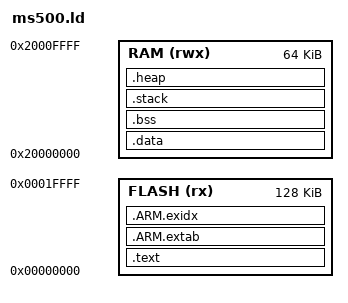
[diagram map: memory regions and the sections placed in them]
ENTRY(Reset_Handler)
/* Library configurations */
GROUP(libgcc.a libc.a libm.a libnosys.a)


StackSize = 0x800;
HeapSize  = 0x800;

/* Linker script to configure memory regions. */
MEMORY
{
    FLASH (rx) : ORIGIN = 0x00000000, LENGTH = 128K
    RAM (rwx)  : ORIGIN = 0x20000000, LENGTH = 64K
}

/* Library configurations */
GROUP(libgcc.a libc.a libm.a libnosys.a)

/* Linker script to place sections and symbol values. Should be used together
 * with other linker script that defines memory regions FLASH and RAM.
 * It references following symbols, which must be defined in code:
 *   Reset_Handler : Entry of reset handler
 *
 * It defines following symbols, which code can use without definition:
 *   __exidx_start
 *   __exidx_end
 *   __copy_table_start__
 *   __copy_table_end__
 *   __zero_table_start__
 *   __zero_table_end__
 *   __etext
 *   __data_start__
 *   __preinit_array_start
 *   __preinit_array_end
 *   __init_array_start
 *   __init_array_end
 *   __fini_array_start
 *   __fini_array_end
 *   __data_end__
 *   __bss_start__
 *   __bss_end__
 *   __end__
 *   end
 *   __HeapLimit
 *   __StackLimit
 *   __StackTop
 *   __stack
 *   __Vectors_End
 *   __Vectors_Size
 */

SECTIONS
{
    .text :
    {
        KEEP(*(.vectors))
        __Vectors_End = .;
        __Vectors_Size = __Vectors_End - __Vectors;
        __end__ = .;

        *(.text*)

        KEEP(*(.init))
        KEEP(*(.fini))

        /* .ctors */
        *crtbegin.o(.ctors)
        *crtbegin?.o(.ctors)
        *(EXCLUDE_FILE(*crtend?.o *crtend.o) .ctors)
        *(SORT(.ctors.*))
        *(.ctors)

        /* .dtors */
        *crtbegin.o(.dtors)
        *crtbegin?.o(.dtors)
        *(EXCLUDE_FILE(*crtend?.o *crtend.o) .dtors)
        *(SORT(.dtors.*))
        *(.dtors)

        *(.rodata*)

        KEEP(*(.eh_frame*))
    } > FLASH

    .ARM.extab :
    {
        *(.ARM.extab* .gnu.linkonce.armextab.*)
    } > FLASH

    __exidx_start = .;
    .ARM.exidx :
    {
        *(.ARM.exidx* .gnu.linkonce.armexidx.*)
    } > FLASH
    __exidx_end = .;

    __etext = .;

    .data : AT (__etext)
    {
        __data_start__ = .;
        *(vtable)
        *(.data*)
        
        . = ALIGN(4);
        /* preinit data */
        PROVIDE_HIDDEN (__preinit_array_start = .);
        KEEP(*(.preinit_array))
        PROVIDE_HIDDEN (__preinit_array_end = .);

        . = ALIGN(4);
        /* init data */
        PROVIDE_HIDDEN (__init_array_start = .);
        KEEP(*(SORT(.init_array.*)))
        KEEP(*(.init_array))
        PROVIDE_HIDDEN (__init_array_end = .);


        . = ALIGN(4);
        /* finit data */
        PROVIDE_HIDDEN (__fini_array_start = .);
        KEEP(*(SORT(.fini_array.*)))
        KEEP(*(.fini_array))
        PROVIDE_HIDDEN (__fini_array_end = .);

        KEEP(*(.jcr*))
        . = ALIGN(4);
        /* All data end */
        __data_end__ = .;

    } > RAM

    .bss :
    {
        . = ALIGN(4);
        __bss_start__ = .;
        *(.bss*)
        *(COMMON)
        . = ALIGN(4);
        __bss_end__ = .;
    } > RAM
    
    .stack (COPY):
    {
        . = ALIGN(4);
        __StackLimit = .;
        *(.stack*);
        . += StackSize - (. - __StackLimit);
    } > RAM 
    __StackTop = ADDR(.stack) + SIZEOF(.stack);
    __StackLimit = ADDR(.stack);
    PROVIDE(__stack = __StackTop);
    
    .heap (COPY):
    {
        __HeapBase = .;
        __end__ = .;
        end = __end__;
        *(.heap*);
        . += HeapSize - (. - __end__);
        __HeapLimit = .;
    } > RAM
}
